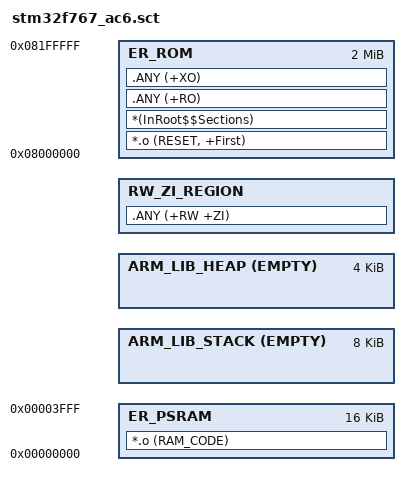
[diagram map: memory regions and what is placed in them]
#! armclang -E --target=arm-arm-none-eabi -mcpu=cortex-m7 -xc
/*
;-------- <<< Use Configuration Wizard in Context Menu >>> -------------------
*/

/*--------------------- Stack / Heap Configuration ---------------------------
; <h> Stack / Heap Configuration
;   <o0> Stack Size (in Bytes) <0x0-0xFFFFFFFF:8>
;   <o1> Heap Size (in Bytes) <0x0-0xFFFFFFFF:8>
;   <o2> gap before heap base (in Bytes) <0x0-0xFFFFFFFF:8>
;   <o3> gap between heap top and stack base (in Bytes) <0x0-0xFFFFFFFF:8>
;   <o4> gap between stack top and rw_zi base (in Bytes) <0x0-0xFFFFFFFF:8>
;   <o5> no init size (in Bytes) <0x0-0xFFFFFFFF:8>
; </h>
 *----------------------------------------------------------------------------*/
#define __STACK_SIZE		0x00002000
#define __HEAP_SIZE			0x00001000
#define	__GAP_INIT	0x100
#define __GAP_HEAP_TOP_STACK_BASE	0x100
#define __GAP_STACK_TOP_RW_BASE		0x100
#define __NO_INIT_SIZE         0x40

#define __FLASH_AXIM_BASE     0x8000000
#define __FLASH_AXIM_SIZE     0x200000
#define __FLASH_ITCM_BASE     0x0200000
#define __FLASH_ITCM_SIZE     0x200000

#define __ITCM_BASE   0x00000000
#define __ITCM_SIZE   0x00004000

#define __DTCM_BASE  0x20000000
#define __DTCM_SIZE  0x00020000

#define __SRAM1_BASE  0x20020000
#define __SRAM1_SIZE  0x0005C000

#define __SRAM2_BASE  0x2007C000
#define __SRAM2_SIZE  0x00004000

#define	__DTCM_S1_S2_RAM_BASE	0x20000000
#define	__DTCM_S1_S2_RAM_SIZE	(__DTCM_SIZE + __SRAM1_SIZE + __SRAM2_SIZE)

#define __RO_BASE         __FLASH_AXIM_BASE
#define __RO_SIZE         __FLASH_AXIM_SIZE

; __DSRAM1_BASE for heap and stack
; Low	-> High
;|	Initial Gap	|	Heap	|	heap_stack gap	|	Stack	|	stack_rwzi gap	|	RW_ZI region 1 |	No_Init region	|

#define __HEAP_BASE			(AlignExpr(__DTCM_S1_S2_RAM_BASE + __GAP_INIT, 8))
#define __HEAP_TOP			(AlignExpr(__HEAP_BASE + __HEAP_SIZE, 8))
#define __STACK_TOP			(AlignExpr(__HEAP_TOP + __GAP_HEAP_TOP_STACK_BASE + __STACK_SIZE, 8))
#define __RWZI_BASE_1		(AlignExpr(__GAP_STACK_TOP_RW_BASE + __STACK_TOP, 8))

#define __RWZI_SIZE_1			(AlignExpr(__DTCM_S1_S2_RAM_SIZE - __GAP_INIT - __HEAP_SIZE - __GAP_HEAP_TOP_STACK_BASE - __STACK_SIZE - __GAP_STACK_TOP_RW_BASE - __NO_INIT_SIZE, 8))

LR_ROM __RO_BASE __RO_SIZE  {
  ER_ROM __RO_BASE __RO_SIZE  {
   *.o (RESET, +First)
   *(InRoot$$Sections)
   .ANY (+RO)
   .ANY (+XO)
  }

  ER_PSRAM __ITCM_BASE __ITCM_SIZE {
    *.o (RAM_CODE)                                ; Matches explicit section name from attributes
  }
  
  ARM_LIB_STACK __STACK_TOP EMPTY -__STACK_SIZE {
  }

  ARM_LIB_HEAP  __HEAP_BASE EMPTY  __HEAP_SIZE {
  }

  RW_ZI_REGION __RWZI_BASE_1 (__RWZI_SIZE_1)  {
   .ANY (+RW +ZI)
  }
}
